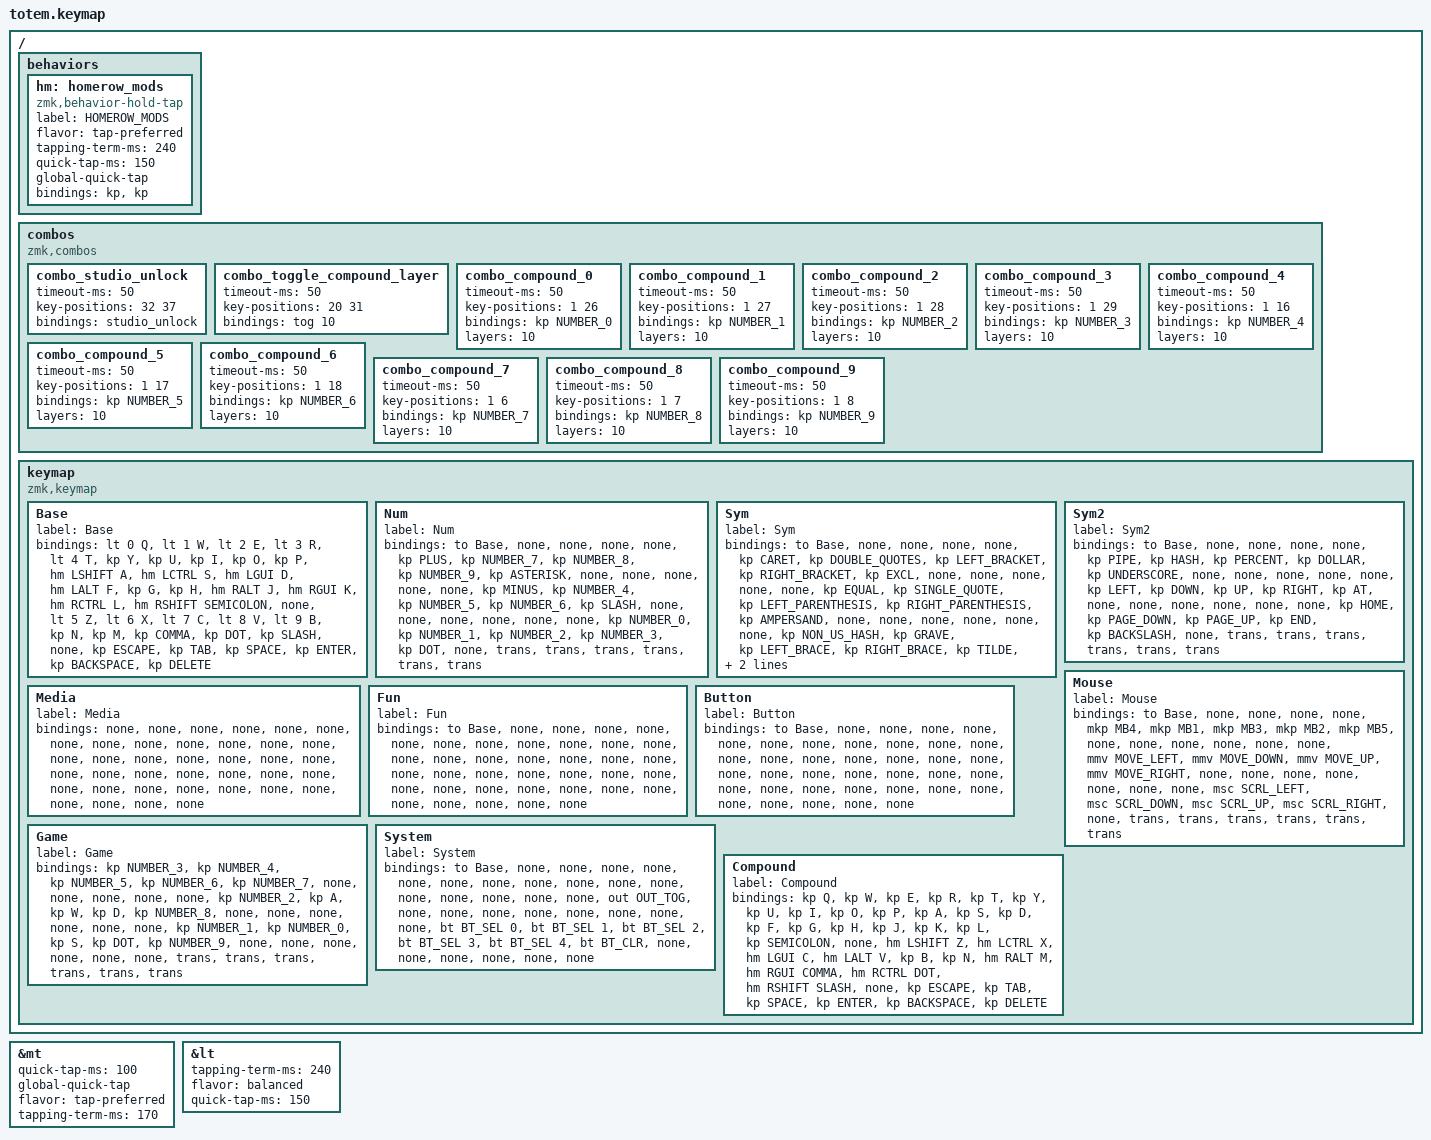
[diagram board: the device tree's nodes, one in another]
// custom keymap for totem

#include <behaviors.dtsi>
#include <dt-bindings/zmk/keys.h>
#include <dt-bindings/zmk/bt.h>
#include <dt-bindings/zmk/outputs.h>
#include <dt-bindings/zmk/ext_power.h>

// defines for pointing layer, must be put BEFORE the include.
#define ZMK_POINTING_DEFAULT_MOVE_VAL 1500  // default: 600
#define ZMK_POINTING_DEFAULT_SCRL_VAL 20    // default: 10

#include <dt-bindings/zmk/pointing.h>

#define Base        0
#define Num         1
#define Sym         2
#define Sym2        3
#define Mouse       4
#define Media       5
#define Fun         6
#define Button      7
#define Game        8
#define System      9
#define Compound    10

&mt {
    quick-tap-ms = <100>;
    global-quick-tap;
    flavor = "tap-preferred";
    tapping-term-ms = <170>;
};

&lt {
    tapping-term-ms = <240>;
    flavor = "balanced";
    quick-tap-ms = <150>;
};

/ {

    behaviors {
        hm: homerow_mods {
            compatible = "zmk,behavior-hold-tap";
            label = "HOMEROW_MODS";
            #binding-cells = <2>;
            flavor = "tap-preferred";
            tapping-term-ms = <240>;
            quick-tap-ms = <150>;
            global-quick-tap;
            bindings =
                <&kp>,
                <&kp>;
        };
    };

    combos {
        compatible = "zmk,combos";
        combo_studio_unlock {
            timeout-ms = <50>;
            key-positions = <32 37>;
            bindings = <&studio_unlock>;
        };
        combo_toggle_compound_layer {
            timeout-ms = <50>;
            key-positions = <20 31>;
            bindings = <&tog 10>;
        };
        combo_compound_0 {
            timeout-ms = <50>;
            key-positions = <1 26>;
            bindings = <&kp NUMBER_0>;
            layers = <10>;
        };
        combo_compound_1 {
            timeout-ms = <50>;
            key-positions = <1 27>;
            bindings = <&kp NUMBER_1>;
            layers = <10>;
        };
        combo_compound_2 {
            timeout-ms = <50>;
            key-positions = <1 28>;
            bindings = <&kp NUMBER_2>;
            layers = <10>;
        };
        combo_compound_3 {
            timeout-ms = <50>;
            key-positions = <1 29>;
            bindings = <&kp NUMBER_3>;
            layers = <10>;
        };
        combo_compound_4 {
            timeout-ms = <50>;
            key-positions = <1 16>;
            bindings = <&kp NUMBER_4>;
            layers = <10>;
        };
        combo_compound_5 {
            timeout-ms = <50>;
            key-positions = <1 17>;
            bindings = <&kp NUMBER_5>;
            layers = <10>;
        };
        combo_compound_6 {
            timeout-ms = <50>;
            key-positions = <1 18>;
            bindings = <&kp NUMBER_6>;
            layers = <10>;
        };
        combo_compound_7 {
            timeout-ms = <50>;
            key-positions = <1 6>;
            bindings = <&kp NUMBER_7>;
            layers = <10>;
        };
        combo_compound_8 {
            timeout-ms = <50>;
            key-positions = <1 7>;
            bindings = <&kp NUMBER_8>;
            layers = <10>;
        };
        combo_compound_9 {
            timeout-ms = <50>;
            key-positions = <1 8>;
            bindings = <&kp NUMBER_9>;
            layers = <10>;
        };
    };

    keymap {
        compatible = "zmk,keymap";

    Base {
        label = "Base";
        bindings = <
                &lt 0 Q       
                &lt 1 W       
                &lt 2 E         
                &lt 3 R         
                &lt 4 T                         
                &kp Y        
                &kp U         
                &kp I       
                &kp O               
                &kp P

                &hm LSHIFT A       
                &hm LCTRL S       
                &hm LGUI D         
                &hm LALT F         
                &kp G
                &kp H
                &hm RALT J        
                &hm RGUI K     
                &hm RCTRL L     
                &hm RSHIFT SEMICOLON  
        
                &none  
                &lt 5 Z  
                &lt 6 X  
                &lt 7 C   
                &lt 8 V  
                &lt 9 B                         
                &kp N  
                &kp M   
                &kp COMMA  
                &kp DOT  
                &kp SLASH 
                &none

                &kp ESCAPE  
                &kp TAB     
                &kp SPACE         
                &kp ENTER  
                &kp BACKSPACE
                &kp DELETE
        >;
    };

    Num {
        label = "Num";
        bindings = <
                &to Base      
                &none     
                &none    
                &none    
                &none
                &kp PLUS  
                &kp NUMBER_7  
                &kp NUMBER_8  
                &kp NUMBER_9  
                &kp ASTERISK       

                &none     
                &none    
                &none     
                &none    
                &none
                &kp MINUS     
                &kp NUMBER_4  
                &kp NUMBER_5  
                &kp NUMBER_6  
                &kp SLASH               

                &none  
                &none     
                &none    
                &none    
                &none
                &none
                &kp NUMBER_0         
                &kp NUMBER_1  
                &kp NUMBER_2  
                &kp NUMBER_3  
                &kp DOT           
                &none

                &trans       
                &trans  
                &trans               
                &trans      
                &trans     
                &trans
        >;
    };

    Sym {
        label = "Sym";
        bindings = <
                &to Base      
                &none     
                &none    
                &none    
                &none
                &kp CARET
                &kp DOUBLE_QUOTES
                &kp LEFT_BRACKET  
                &kp RIGHT_BRACKET
                &kp EXCL

                &none      
                &none     
                &none    
                &none    
                &none
                &kp EQUAL
                &kp SINGLE_QUOTE
                &kp LEFT_PARENTHESIS
                &kp RIGHT_PARENTHESIS   
                &kp AMPERSAND

                &none      
                &none     
                &none  
                &none    
                &none    
                &none  
                &kp NON_US_HASH               
                &kp GRAVE               
                &kp LEFT_BRACE  
                &kp RIGHT_BRACE       
                &kp TILDE              
                &none  

                &trans      
                &trans     
                &trans   
                &trans      
                &trans     
                &trans   
        >;
    };

    Sym2 {
        label = "Sym2";
        bindings = <
                &to Base    
                &none    
                &none     
                &none      
                &none                       
                &kp PIPE       
                &kp HASH       
                &kp PERCENT          
                &kp DOLLAR     
                &kp UNDERSCORE              

                &none     
                &none         
                &none       
                &none       
                &none  
                &kp LEFT       
                &kp DOWN       
                &kp UP    
                &kp RIGHT
                &kp AT               

                &none  
                &none     
                &none         
                &none       
                &none       
                &none  
                &kp HOME  
                &kp PAGE_DOWN  
                &kp PAGE_UP      
                &kp END  
                &kp BACKSLASH
                &none

                &trans     
                &trans      
                &trans                   
                &trans  
                &trans         
                &trans
        >;
    };

    Mouse {
        label = "Mouse";
        bindings = <
        // Top Row Left Side
                &to Base  
                &none  
                &none  
                &none  
                &none          
        // Top Row Right Side
                &mkp MB4
                &mkp MB1
                &mkp MB3
                &mkp MB2
                &mkp MB5
        // Mid Row Left Side
                &none  
                &none   
                &none   
                &none   
                &none 
        // Mid Row Right Side
                &none  
                &mmv MOVE_LEFT 
                &mmv MOVE_DOWN 
                &mmv MOVE_UP
                &mmv MOVE_RIGHT
        // Bottom Row Left Side
                &none  
                &none  
                &none  
                &none  
                &none  
                &none         
        // Bottom Row Right Side 
                &none  
                &msc SCRL_LEFT
                &msc SCRL_DOWN
                &msc SCRL_UP
                &msc SCRL_RIGHT
                &none
        // Thumb Cluster Left
                &trans  
                &trans  
                &trans       
        //  Thumb Cluster Right   
                &trans  
                &trans  
                &trans
        >;
    };

    Media {
        label = "Media";
        bindings = <
                &none    
                &none    
                &none     
                &none      
                &none               
                &none            
                &none             
                &none           
                &none      
                &none  

                &none     
                &none               
                &none  
                &none     
                &none               
                &none    
                &none
                &none
                &none
                &none

                &none  
                &none    
                &none    
                &none     
                &none      
                &none               
                &none            
                &none             
                &none           
                &none      
                &none  
                &none
                
                &none     
                &none               
                &none  
                &none     
                &none               
                &none  
        >;
    };

    Fun {
        label = "Fun";
        bindings = <
        // Top Row Left Side
                &to Base  
                &none  
                &none  
                &none  
                &none          
        // Top Row Right Side
                &none  
                &none  
                &none  
                &none  
                &none
        // Mid Row Left Side
                &none  
                &none  
                &none  
                &none  
                &none
        // Mid Row Right Side
                &none  
                &none  
                &none  
                &none  
                &none
        // Bottom Row Left Side
                &none  
                &none  
                &none  
                &none  
                &none  
                &none         
        // Bottom Row Right Side 
                &none  
                &none  
                &none  
                &none  
                &none  
                &none
        // Thumb Cluster Left
                &none  
                &none  
                &none       
        //  Thumb Cluster Right   
                &none  
                &none  
                &none
        >;
    };

    Button {
        label = "Button";
        bindings = <
        // Top Row Left Side
                &to Base  
                &none  
                &none  
                &none  
                &none          
        // Top Row Right Side
                &none  
                &none  
                &none  
                &none  
                &none
        // Mid Row Left Side
                &none  
                &none  
                &none  
                &none  
                &none
        // Mid Row Right Side
                &none  
                &none  
                &none  
                &none  
                &none
        // Bottom Row Left Side
                &none  
                &none  
                &none  
                &none  
                &none  
                &none         
        // Bottom Row Right Side 
                &none  
                &none  
                &none  
                &none  
                &none  
                &none
        // Thumb Cluster Left
                &none  
                &none  
                &none       
        //  Thumb Cluster Right   
                &none  
                &none  
                &none
        >;
    };

    Game {
        label = "Game";
        bindings = <
        // Top Row Left Side
                &kp NUMBER_3
                &kp NUMBER_4
                &kp NUMBER_5
                &kp NUMBER_6
                &kp NUMBER_7     
        // Top Row Right Side
                &none
                &none
                &none
                &none
                &none 
        // Mid Row Left Side
                &kp NUMBER_2
                &kp A
                &kp W
                &kp D
                &kp NUMBER_8
        // Mid Row Right Side
                &none
                &none
                &none
                &none
                &none 
        // Bottom Row Left Side
                &none
                &kp NUMBER_1
                &kp NUMBER_0
                &kp S
                &kp DOT
                &kp NUMBER_9
        // Bottom Row Right Side 
                &none
                &none
                &none
                &none
                &none 
                &none
        // Thumb Cluster Left
                &trans
                &trans
                &trans    
        //  Thumb Cluster Right   
                &trans
                &trans
                &trans
        >;
    };

    System {
        label = "System";
        bindings = <
        // Top Row Left Side
                &to Base  
                &none  
                &none  
                &none  
                &none          
        // Top Row Right Side
                &none  
                &none  
                &none  
                &none  
                &none
        // Mid Row Left Side
                &none  
                &none  
                &none  
                &none  
                &none
        // Mid Row Right Side
                &none  
                &none  
                &out OUT_TOG
                &none  
                &none
        // Bottom Row Left Side
                &none  
                &none  
                &none  
                &none  
                &none  
                &none         
        // Bottom Row Right Side 
                &bt BT_SEL 0
                &bt BT_SEL 1
                &bt BT_SEL 2
                &bt BT_SEL 3
                &bt BT_SEL 4
                &bt BT_CLR
        // Thumb Cluster Left
                &none  
                &none  
                &none       
        //  Thumb Cluster Right   
                &none  
                &none  
                &none
        >;
    };
    Compound {
        label = "Compound";
        bindings = <
                &kp Q       
                &kp W       
                &kp E         
                &kp R         
                &kp T                         
                &kp Y        
                &kp U         
                &kp I       
                &kp O               
                &kp P

                &kp A       
                &kp S     
                &kp D         
                &kp F         
                &kp G                         
                &kp H        
                &kp J     
                &kp K     
                &kp L         
                &kp SEMICOLON  
        
                &none  
                &hm LSHIFT Z  
                &hm LCTRL X  
                &hm LGUI C   
                &hm LALT V  
                &kp B                         
                &kp N  
                &hm RALT M   
                &hm RGUI COMMA  
                &hm RCTRL DOT  
                &hm RSHIFT SLASH 
                &none

                &kp ESCAPE  
                &kp TAB     
                &kp SPACE         
                &kp ENTER  
                &kp BACKSPACE
                &kp DELETE
        >;
    };
  };
};
